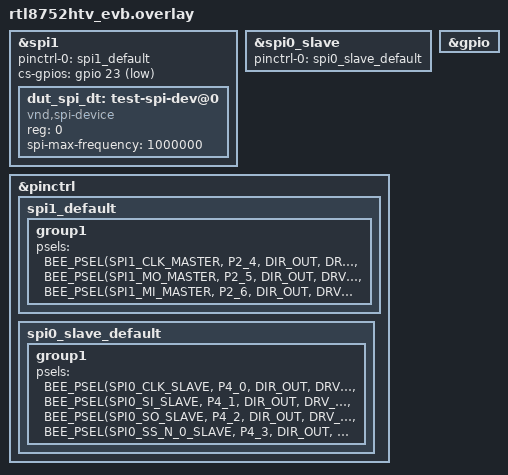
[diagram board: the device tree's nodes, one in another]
/*
 * Copyright (c) 2025 Nordic Semiconductor
 *
 * SPDX-License-Identifier: Apache-2.0
 */

&spi1 {
	status = "okay";
	pinctrl-0 = <&spi1_default>;
	pinctrl-names = "default";
	cs-gpios = <&gpio 23 GPIO_ACTIVE_LOW>;
/* dma is optional
	dmas =  <&dma0 0 6 0x10021>, <&dma0 1 7 0xa>;
	dma-names = "tx", "rx";
*/
	dut_spi_dt: test-spi-dev@0 {
		compatible = "vnd,spi-device";
		reg = <0>;
		spi-max-frequency = <1000000>;
	};
};

dut_spis: &spi0_slave {
	status = "okay";
/* dma is optional
	dmas =  <&dma0 0 4 0x10021>, <&dma0 1 5 0xa>;
	dma-names = "tx", "rx";
*/
	pinctrl-0 = <&spi0_slave_default>;
	pinctrl-names = "default";
};

&gpio {
	status = "okay";
};

/* dma is optional
&dma0 {
	status = "okay";
};
*/

&pinctrl {
	spi1_default: spi1_default {
		group1 {
			psels = <BEE_PSEL(SPI1_CLK_MASTER, P2_4, DIR_OUT, DRV_HIGH, PULL_UP)>,
			<BEE_PSEL(SPI1_MO_MASTER, P2_5, DIR_OUT, DRV_HIGH, PULL_UP)>,
			<BEE_PSEL(SPI1_MI_MASTER, P2_6, DIR_OUT, DRV_HIGH, PULL_UP)>;
		};
	};

	spi0_slave_default: spi0_slave_default {
		group1 {
			psels = <BEE_PSEL(SPI0_CLK_SLAVE, P4_0, DIR_OUT, DRV_HIGH, PULL_UP)>,
			<BEE_PSEL(SPI0_SI_SLAVE, P4_1, DIR_OUT, DRV_HIGH, PULL_UP)>,
			<BEE_PSEL(SPI0_SO_SLAVE, P4_2, DIR_OUT, DRV_HIGH, PULL_UP)>,
			<BEE_PSEL(SPI0_SS_N_0_SLAVE, P4_3, DIR_OUT, DRV_HIGH, PULL_UP)>;
		};
	};
};
